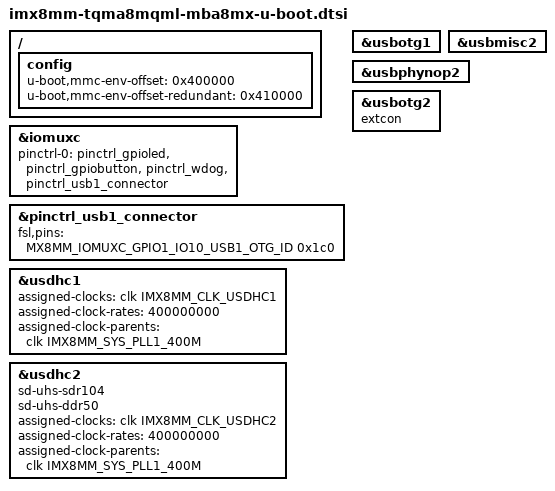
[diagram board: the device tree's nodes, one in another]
// SPDX-License-Identifier: GPL-2.0-or-later OR MIT
/*
 * Copyright (c) 2020-2023 TQ-Systems GmbH <u-boot@ew.tq-group.com>,
 * D-82229 Seefeld, Germany.
 */

#include "imx8mm-tqma8mqml-u-boot.dtsi"
#include "mba8mx-u-boot.dtsi"

/ {
	config {
		/* 32 kiB redundant env */
		u-boot,mmc-env-offset = <0x400000>;
		u-boot,mmc-env-offset-redundant = <0x410000>;
	};
};

&iomuxc {
	pinctrl-names = "default";
	pinctrl-0 = <&pinctrl_gpioled>,
		    <&pinctrl_gpiobutton>,
		    <&pinctrl_wdog>,
		    <&pinctrl_usb1_connector>;
};

/*
 * USB OTG ID to support ci_udc_otg_phy_mode
 * needs USBNC CTRL2, bit DIG_ID_SEL configured
 */
&pinctrl_usb1_connector {
	fsl,pins = <MX8MM_IOMUXC_GPIO1_IO10_USB1_OTG_ID	0x1c0>;
};

&usbotg1 {
	u-boot,dm-spl;
};

&usbmisc2 {
	u-boot,dm-spl;
};

&usbphynop2 {
	u-boot,dm-spl;
};

&usbotg2 {
	u-boot,dm-spl;
	extcon;
};

&usdhc1 {
	u-boot,dm-spl;
	assigned-clocks = <&clk IMX8MM_CLK_USDHC1>;
	assigned-clock-rates = <400000000>;
	assigned-clock-parents = <&clk IMX8MM_SYS_PLL1_400M>;
};

&usdhc2 {
	u-boot,dm-spl;
	sd-uhs-sdr104;
	sd-uhs-ddr50;
	assigned-clocks = <&clk IMX8MM_CLK_USDHC2>;
	assigned-clock-rates = <400000000>;
	assigned-clock-parents = <&clk IMX8MM_SYS_PLL1_400M>;
};

